# f28004x_cla_only_regs register map
Vendor: Texas Instruments
Peripheral module from a debugger description file (folder C2000).
Address unit: 16 bits
Registers are 16-bit, read-write, no defined reset value unless marked. A register's access mark holds for its fields unless they carry their own. Offsets are as the file gives them; lines under a group give offsets from that group; [hi:lo] are bit positions; {n}, {i} and the like mark numbered series; 'fields as' and 'values as' point back to an identical list; <NAME> marks a mode.

## CLA_ONLY_REGS — CLA ONLY Registers
0x80 _MVECTBGRNDACTIVE ro — Active register for MVECTBGRND.
  [15:0] i16 — Active register for the Background Task Vector
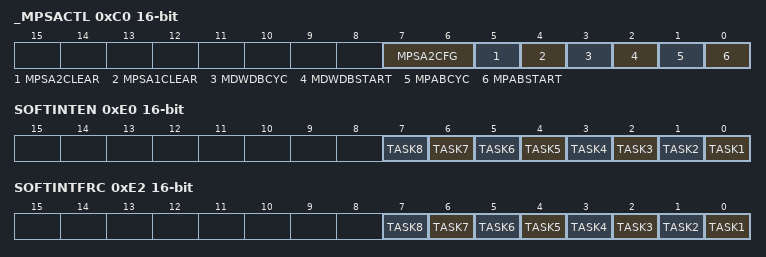
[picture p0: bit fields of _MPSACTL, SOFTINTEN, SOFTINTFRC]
0xC0 _MPSACTL access not given — CLA PSA Control Register
  [7:6] MPSA2CFG rw — PSA2 Polynomial Configuration
  [5] MPSA2CLEAR — PSA2 Clear (access R=0/W=1)
  [4] MPSA1CLEAR — PSA1 clear (access R=0/W=1)
  [3] MDWDBCYC rw — DWDB logging into PSA2 is on every cycle.
  [2] MDWDBSTART rw — Start logging DWDB onto PSA2
  [1] MPABCYC rw — PAB logging into PSA1 is on every cycle or when PAB changes.
  [0] MPABSTART rw — Start logging PAB onto PSA1
0xC2 _MPSA1 32-bit — CLA PSA1 Register
  [31:0] i32 — PSA1
0xC4 _MPSA2 32-bit — CLA PSA2 Register
  [31:0] i32 — PSA2
0xE0 SOFTINTEN — CLA Software Interrupt Enable Register
  [n-1] TASK{n} (n=1..8) — Configure Software Interrupt or End of Task interrupt.
0xE2 SOFTINTFRC access not given — CLA Software Interrupt Force Register
  [n-1] TASK{n} (n=1..8) — Force CLA software interrupt for the corresponding task. (access R=0/W=1)
